# f28003x_fsi_rx_regs register map
Vendor: Texas Instruments
Peripheral module from a debugger description file (folder C2000).
Address unit: 16 bits
Registers are 16-bit, read-write, no defined reset value unless marked. A register's access mark holds for its fields unless they carry their own. Offsets are as the file gives them; lines under a group give offsets from that group; [hi:lo] are bit positions; {n}, {i} and the like mark numbered series; 'fields as' and 'values as' point back to an identical list; <NAME> marks a mode.

## FSI_RX_REGS — FSI RX Registers
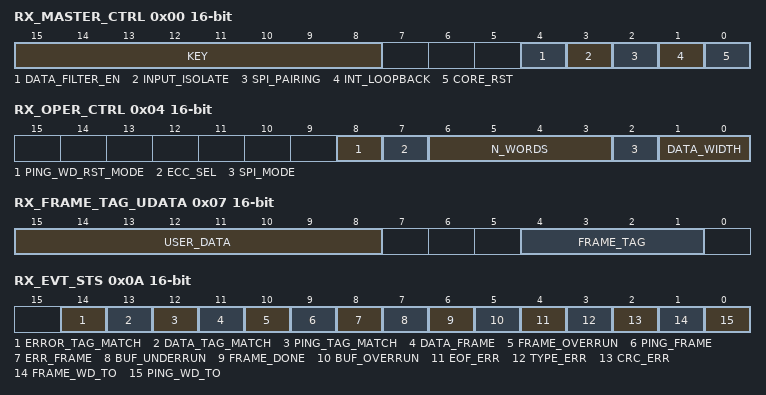
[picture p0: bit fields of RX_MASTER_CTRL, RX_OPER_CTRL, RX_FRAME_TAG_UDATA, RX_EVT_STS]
0x00 RX_MASTER_CTRL — Receive master control register
  [15:8] KEY — Write Key
  [4] DATA_FILTER_EN — Data Filter Enable
  [3] INPUT_ISOLATE — ISOLATE Input signals
  [2] SPI_PAIRING — Clock Pairing for SPI-like Behaviour
  [1] INT_LOOPBACK — Internal Loopback Enable
  [0] CORE_RST — Receiver Master Core Reset
0x04 RX_OPER_CTRL — Receive operation control register
  [8] PING_WD_RST_MODE — Ping Watchdog Timeout Mode Select
  [7] ECC_SEL — ECC Data Width Select
  [6:3] N_WORDS — Number of Words to be Received
  [2] SPI_MODE — SPI Mode Enable
  [1:0] DATA_WIDTH — Receive Data Width Select
0x06 RX_FRAME_INFO ro — Receive frame control register
  [3:0] FRAME_TYPE — Received Frame Type
0x07 RX_FRAME_TAG_UDATA ro — Receive frame tag and user data register
  [15:8] USER_DATA — Received User Data
  [4:1] FRAME_TAG — Received Frame Tag
0x08 RX_DMA_CTRL — Receive DMA event control register
  [0] DMA_EVT_EN — DMA Event Enable
0x0A RX_EVT_STS ro — Receive event and error status flag register
  [14] ERROR_TAG_MATCH — Error Tag Match Flag
  [13] DATA_TAG_MATCH — Data Tag Match Flag
  [12] PING_TAG_MATCH — Ping Tag Match Flag
  [11] DATA_FRAME — Data Frame Received Flag
  [10] FRAME_OVERRUN — Frame Overrun Flag
  [9] PING_FRAME — Ping Frame Received Flag
  [8] ERR_FRAME — Error Frame Received Flag
  [7] BUF_UNDERRUN — Receive Buffer Underrun Flag
  [6] FRAME_DONE — Frame Done Flag
  [5] BUF_OVERRUN — Receive Buffer Overrun Flag
  [4] EOF_ERR — End-of-Frame Error Flag
  [3] TYPE_ERR — Frame Type Error Flag
  [2] CRC_ERR — CRC Error Flag
  [1] FRAME_WD_TO — Frame Watchdog Timeout Flag.
  [0] PING_WD_TO — Ping Watchdog Timeout Flag
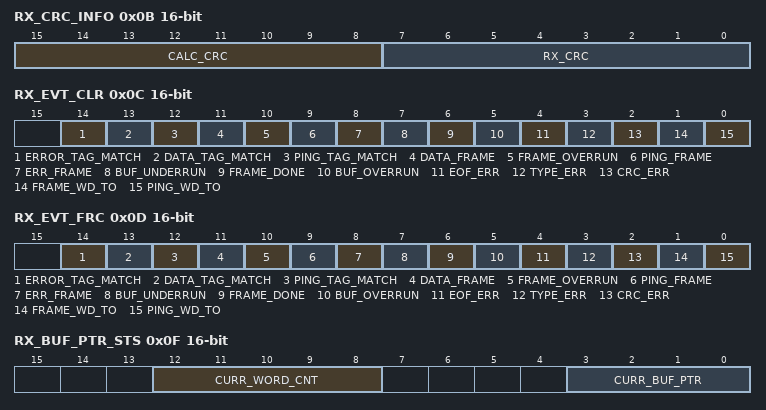
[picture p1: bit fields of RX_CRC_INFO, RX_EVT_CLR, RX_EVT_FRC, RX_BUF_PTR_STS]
0x0B RX_CRC_INFO ro — Receive CRC info of received and computed CRC
  [15:8] CALC_CRC — Hardware Calculated CRC
  [7:0] RX_CRC — Received CRC Value
0x0C RX_EVT_CLR — Receive event and error clear register
  [14] ERROR_TAG_MATCH — Error Tag Match Flag Clear
  [13] DATA_TAG_MATCH — Data Tag Match Flag Clear
  [12] PING_TAG_MATCH — Ping Tag Match Flag Clear
  [11] DATA_FRAME — Data Frame Received Flag Clear
  [10] FRAME_OVERRUN — Frame Overrun Flag Clear
  [9] PING_FRAME — PING Frame Received Flag Clear
  [8] ERR_FRAME — Error Frame Received Flag Clear
  [7] BUF_UNDERRUN — Receive Buffer Underrun Flag Clear
  [6] FRAME_DONE — Frame Done Flag Clear
  [5] BUF_OVERRUN — Receive Buffer Overrun Flag Clear
  [4] EOF_ERR — End-of-Frame Error Flag Clear
  [3] TYPE_ERR — Frame Type Error Flag Clear
  [2] CRC_ERR — CRC Error Flag Clear
  [1] FRAME_WD_TO — Frame Watchdog Timeout Flag Clear
  [0] PING_WD_TO — Ping Watchdog Timeout Flag Clear
0x0D RX_EVT_FRC — Receive event and error flag force register
  [14] ERROR_TAG_MATCH — Error Tag Match Flag Force
  [13] DATA_TAG_MATCH — Data Tag Match Flag Force
  [12] PING_TAG_MATCH — Ping Tag Match Flag Force
  [11] DATA_FRAME — Data Frame Received Flag Force
  [10] FRAME_OVERRUN — Frame Overrun Flag Force
  [9] PING_FRAME — Ping Frame Received Flag Force
  [8] ERR_FRAME — Error Frame Received Flag Force
  [7] BUF_UNDERRUN — Receive Buffer Underrun Flag Force
  [6] FRAME_DONE — Frame Done Flag Force
  [5] BUF_OVERRUN — Receive Buffer Overrun Flag Force
  [4] EOF_ERR — End-of-Frame Error Flag Force
  [3] TYPE_ERR — Frame Type Error Flag Force
  [2] CRC_ERR — CRC Error Flag Force
  [1] FRAME_WD_TO — Frame Watchdog Timeout Flag Force
  [0] PING_WD_TO — Ping Watchdog Timeout Flag Force
0x0E RX_BUF_PTR_LOAD — Receive buffer pointer load register
  [3:0] BUF_PTR_LOAD — Load value for receive buffer pointer
0x0F RX_BUF_PTR_STS ro — Receive buffer pointer status register
  [12:8] CURR_WORD_CNT — Available Words in Buffer
  [3:0] CURR_BUF_PTR — Current Buffer Pointer Index
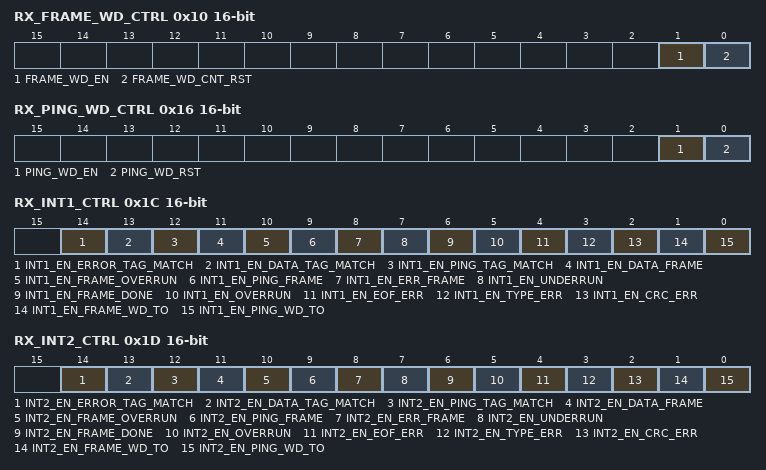
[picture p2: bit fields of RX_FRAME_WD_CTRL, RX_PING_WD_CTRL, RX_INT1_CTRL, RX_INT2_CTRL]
0x10 RX_FRAME_WD_CTRL — Receive frame watchdog control register
  [1] FRAME_WD_EN — Frame Watchdog Counter Enable
  [0] FRAME_WD_CNT_RST — Frame Watchdog Counter Reset
0x12 RX_FRAME_WD_REF 32-bit — Receive frame watchdog counter reference
  [31:0] FRAME_WD_REF — Frame Watchdog Counter Reference Value
0x14 RX_FRAME_WD_CNT 32-bit ro — Receive frame watchdog current count
  [31:0] FRAME_WD_CNT — Frame Watchdog Counter Value
0x16 RX_PING_WD_CTRL — Receive ping watchdog control register
  [1] PING_WD_EN — Ping Watchdog Counter Enable
  [0] PING_WD_RST — Ping Watchdog Counter Reset
0x17 RX_PING_TAG ro — Receive ping tag register
  [4:1] PING_TAG — Ping Frame Tag
0x18 RX_PING_WD_REF 32-bit — Receive ping watchdog counter reference
  [31:0] PING_WD_REF — PING Watchdog Counter Reference Value
0x1A RX_PING_WD_CNT 32-bit ro — Receive pingwatchdog current count
  [31:0] PING_WD_CNT — Ping Watchdog Counter Value
0x1C RX_INT1_CTRL — Receive interrupt control register for RX_INT1
  [14] INT1_EN_ERROR_TAG_MATCH — Enable Error Frame Tag Matched Interrupt to INT1
  [13] INT1_EN_DATA_TAG_MATCH — Enable Data Frame Tag Matched Interrupt to INT1
  [12] INT1_EN_PING_TAG_MATCH — Enable Ping Frame Tag Matched Interrupt to INT1
  [11] INT1_EN_DATA_FRAME — Enable Data Frame Received Interrupt to INT1
  [10] INT1_EN_FRAME_OVERRUN — Enable Frame Overrun Interrupt to INT1
  [9] INT1_EN_PING_FRAME — Enable Ping Frame Received Interrupt to INT1
  [8] INT1_EN_ERR_FRAME — Enable Error Frame Received Interrupt to INT1
  [7] INT1_EN_UNDERRUN — Enable Buffer Underrun Interrupt to INT1
  [6] INT1_EN_FRAME_DONE — Enable Frame Done Interrupt to INT1
  [5] INT1_EN_OVERRUN — Enable Receive Buffer Overrun Interrupt to INT1
  [4] INT1_EN_EOF_ERR — Enable End-of-Frame Error Interrupt to INT1
  [3] INT1_EN_TYPE_ERR — Enable Frame Type Error Interrupt to INT1
  [2] INT1_EN_CRC_ERR — Enable CRC Error Interrupt to INT1
  [1] INT1_EN_FRAME_WD_TO — Enable Frame Watchdog Timeout Interrupt to INT1
  [0] INT1_EN_PING_WD_TO — Enable Ping Watchdog Timeout Interrupt to INT1
0x1D RX_INT2_CTRL — Receive interrupt control register for RX_INT2
  [14] INT2_EN_ERROR_TAG_MATCH — Enable Error Frame Tag Matched Interrupt to INT2
  [13] INT2_EN_DATA_TAG_MATCH — Enable Data Frame Tag Matched Interrupt to INT2
  [12] INT2_EN_PING_TAG_MATCH — Enable Ping Frame Tag Matched Interrupt to INT2
  [11] INT2_EN_DATA_FRAME — Enable Data Frame Received Interrupt to INT2
  [10] INT2_EN_FRAME_OVERRUN — Enable Frame Overrun Interrupt to INT2
  [9] INT2_EN_PING_FRAME — Enable Ping Frame Received Interrupt to INT2
  [8] INT2_EN_ERR_FRAME — Enable Error Frame Received Interrupt to INT2
  [7] INT2_EN_UNDERRUN — Enable Buffer Underrun Interrupt to INT2
  [6] INT2_EN_FRAME_DONE — Enable Frame Done Interrupt to INT2
  [5] INT2_EN_OVERRUN — Enable Buffer Overrun Interrupt to INT2
  [4] INT2_EN_EOF_ERR — Enable End-of-Frame Error Interrupt to INT2
  [3] INT2_EN_TYPE_ERR — Enable Frame Type Error Interrupt to INT2
  [2] INT2_EN_CRC_ERR — Enable CRC Errror Interrupt to INT2
  [1] INT2_EN_FRAME_WD_TO — Enable Frame Watchdog Timeout Interrupt to INT2
  [0] INT2_EN_PING_WD_TO — Enable Ping Watchdog Timeout Interrupt to INT2
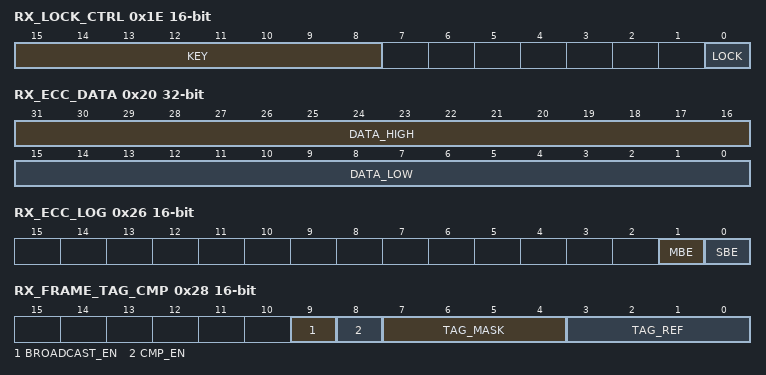
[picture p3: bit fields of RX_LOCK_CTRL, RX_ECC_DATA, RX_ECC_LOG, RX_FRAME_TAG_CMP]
0x1E RX_LOCK_CTRL — Receive lock control register
  [15:8] KEY — Write Key
  [0] LOCK — Control Register Lock Enable
0x20 RX_ECC_DATA 32-bit — Receive ECC data register
  [31:16] DATA_HIGH — ECC Data Upper 16 Bits
  [15:0] DATA_LOW — ECC Data Lower 16 Bits
0x22 RX_ECC_VAL — Receive ECC value register
  [6:0] ECC_VAL — Computed ECC Value
0x24 RX_ECC_SEC_DATA 32-bit ro — Receive ECC corrected data register
  [31:0] SEC_DATA — ECC Single Error Corrected Data
0x26 RX_ECC_LOG ro — Receive ECC log and status register
  [1] MBE — Multiple Bit Errors Detected
  [0] SBE — Single Bit Error Detected
0x28 RX_FRAME_TAG_CMP — Receive frame tag compare register
  [9] BROADCAST_EN — Broadcast Enable
  [8] CMP_EN — Frame Tag Compare Enable
  [7:4] TAG_MASK — Frame Tag Mask
  [3:0] TAG_REF — Frame Tag Reference
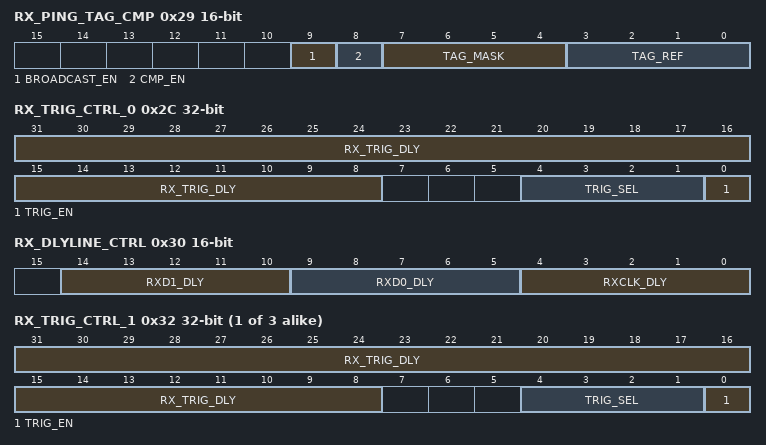
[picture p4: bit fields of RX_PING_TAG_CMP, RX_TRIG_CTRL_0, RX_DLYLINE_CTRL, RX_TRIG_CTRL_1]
0x29 RX_PING_TAG_CMP — Receive ping tag compare register
  [9] BROADCAST_EN — Broadcast Enable
  [8] CMP_EN — Ping Tag Compare Enable
  [7:4] TAG_MASK — Ping Tag Mask
  [3:0] TAG_REF — Ping Tag Reference
0x2C RX_TRIG_CTRL_0 32-bit — Receive Trigger Control register 0
  [31:8] RX_TRIG_DLY — Delay for Trigger generation
  [4:1] TRIG_SEL — Input Select for Trigger
  [0] TRIG_EN — Enable Trigger Function
0x2E RX_TRIG_WIDTH_0 32-bit — Receive Trigger Wdith register 0
  [15:0] RX_TRIG_WIDTH — Output Pulse Width
0x30 RX_DLYLINE_CTRL — Receive delay line control register
  [14:10] RXD1_DLY — Delay Line Tap Select for RXD1
  [9:5] RXD0_DLY — Delay Line Tap Select for RXD0
  [4:0] RXCLK_DLY — Delay Line Tap Select for RXCLK
{0x30+2i} RX_TRIG_CTRL_{i} 32-bit (i=1..3) — Receive Trigger Control register {i}
  fields as RX_TRIG_CTRL_0
0x38 RX_VIS_1 32-bit ro — Receive debug visibility register 1
  [3] RX_CORE_STS — Receiver Core Status
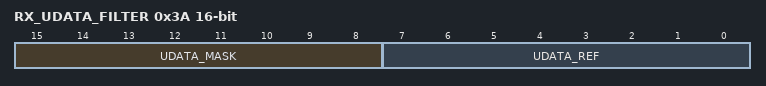
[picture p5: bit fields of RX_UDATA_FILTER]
0x3A RX_UDATA_FILTER — Receive User Data Filter Control register
  [15:8] UDATA_MASK — UserData mask value
  [7:0] UDATA_REF — UserData reference value
0x40 RX_BUF_BASE ro — Base address for receive data buffer
  [15:0] BASE_ADDRESS — Receive Data Buffer Base Address
